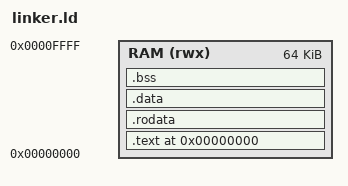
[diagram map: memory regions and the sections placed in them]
OUTPUT_ARCH(riscv)
ENTRY(_start)

MEMORY
{
    RAM (rwx) : ORIGIN = 0x00000000, LENGTH = 64K
}

STACK_SIZE = 4K;

SECTIONS
{
    . = ORIGIN(RAM);

    .text : ALIGN(4)
    {
        KEEP(*(.text.init))
        *(.text .text.*)
    } > RAM

    .rodata : ALIGN(4)
    {
        *(.rodata .rodata.*)
    } > RAM

    .data : ALIGN(4)
    {
        *(.data .data.*)
    } > RAM

    .bss (NOLOAD) : ALIGN(4)
    {
        _bss_start = .;
        *(.bss .bss.*)
        *(COMMON)
        . = ALIGN(4);
        _bss_end = .;
    } > RAM

    _end = .;
    _stack_top = ORIGIN(RAM) + LENGTH(RAM);
    _stack_bottom = _stack_top - STACK_SIZE;

    ASSERT(_end <= _stack_bottom, "program sections overlap the stack")
}
